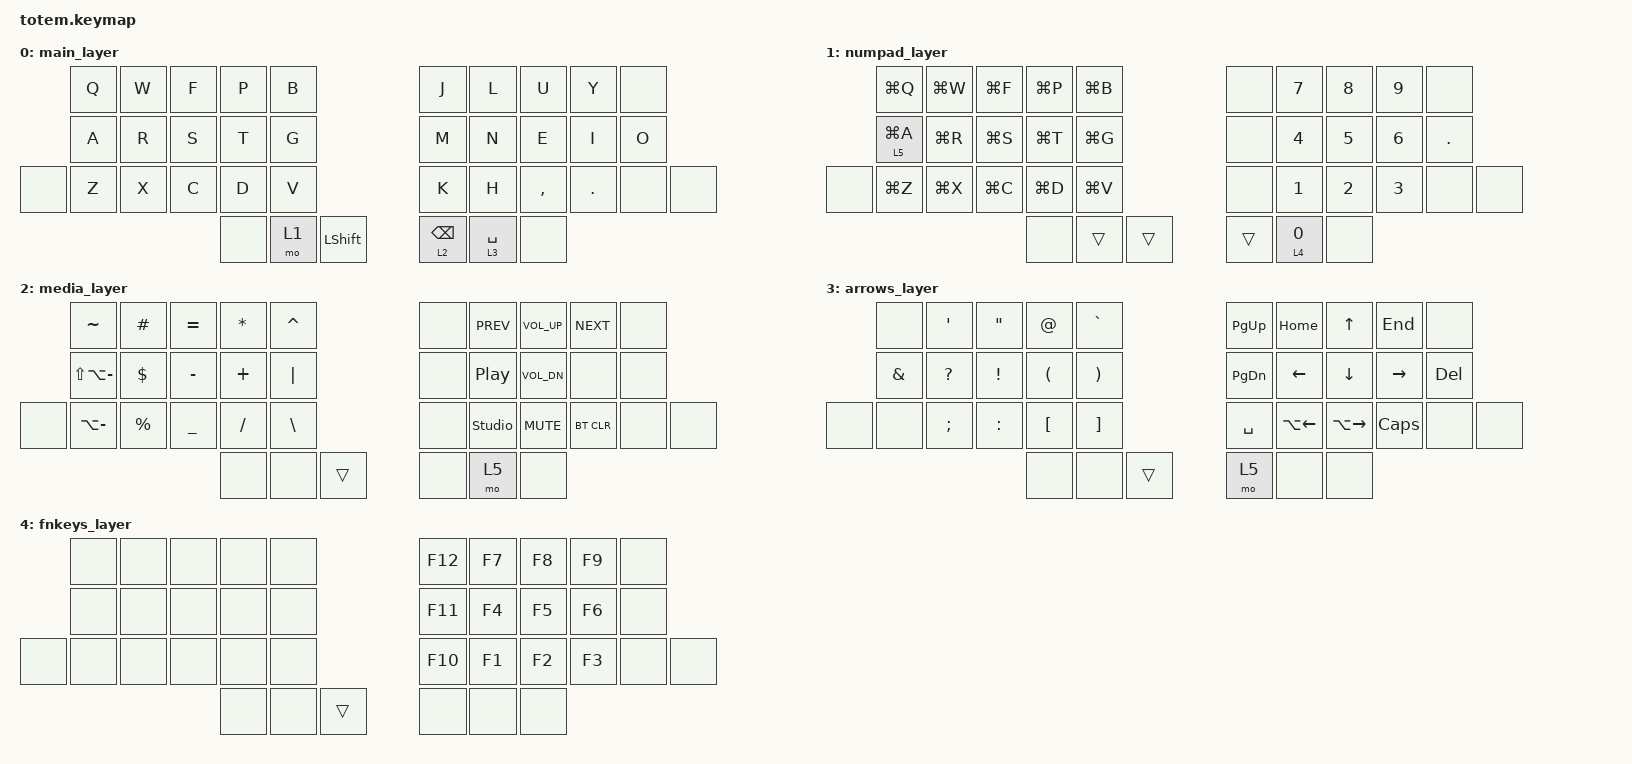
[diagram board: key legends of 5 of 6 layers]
//
//                                                        ▀▀▀▀▀     ▀▀▀▀▀          ▀▀█▀▀
//                                                        ▄▀▀▀▄  ▄  ▄▀▀▀▄  ▄  ▄▀▀▀▄  █  ▄▀▀▀▄
//                                                        █   █  █  █   █  █  █   █  █  █   █
//                                                         ▀▀▀   █   ▀▀▀   █   ▀▀▀   ▀   ▀▀▀
//                                                               █      ▄▄▄█▄▄▄    █   █  
//                                                               ▀      █  █  █     █▄█
//                                                             ▀▀▀▀▀    █  █  █      ▀
//                                                                      ▀  ▀  ▀
//
// ▄▄▄▄▄▄▄▄▄▄▄▄▄▄▄▄▄▄▄▄▄▄▄▄▄▄▄▄▄▄▄▄▄▄▄▄▄▄▄▄▄▄▄▄▄▄▄▄▄▄▄▄▄▄▄▄▄▄▄▄▄▄▄▄▄▄▄▄▄▄▄▄▄▄▄▄▄▄▄▄▄▄▄▄▄▄▄▄▄▄▄▄▄▄▄▄▄▄▄▄▄▄▄▄▄▄▄▄▄▄▄▄▄▄▄▄▄▄▄▄▄▄▄▄▄▄▄▄▄▄▄▄▄▄▄▄▄▄▄▄▄▄▄▄▄▄▄▄▄
       

#include <behaviors.dtsi> 
#include <dt-bindings/zmk/keys.h>
#include <dt-bindings/zmk/bt.h>
#include <dt-bindings/zmk/outputs.h>

#define MAIN 0
#define NUMPAD 1
#define MEDIA 2
#define ARROWS 3
#define FKEYS 4
#define LEFTARROWS 5

/*
     |  0 |  1 |  2 |  3 |  4 |    |  5 |  6 |  7 |  8 |  9 |
     | 10 | 11 | 12 | 13 | 14 |    | 15 | 16 | 17 | 18 | 19 |
| 20 | 21 | 22 | 23 | 24 | 25 |    | 26 | 27 | 28 | 29 | 30 | 31 | 
     |    |    | 32 | 33 | 34 |    | 35 | 36 | 37 |    |    | 
                                                                  */

/ {
    kscan0: kscan_0 {
        compatible = "zmk,kscan-gpio-matrix";
        label = "KSCAN";
        diode-direction = "col2row";
        wakeup-source;
    };
};


/ {
    combos {
        compatible = "zmk,combos";


        //Modifiers – Left Hand
        combo_lgui {
            timeout-ms = <25>;
            key-positions = <3 13>;
            layers = <0 1 2 3 4 5>;
            bindings = <&kp LGUI>;
        };
        combo_lalt {
            timeout-ms = <25>;
            key-positions = <2 12>;
            layers = <0 1 2 3 4 5>;
            bindings = <&kp LALT>;
        };
        combo_lctl {
            timeout-ms = <25>;
            key-positions = <1 11>;
            layers = <0 1 2 3 4 5>;
            bindings = <&kp LCTRL>;
        };
        combo_lctlalt {
            timeout-ms = <25>;
            key-positions = <1 11 2 12>;
            layers = <0 1 2 3 4 5>;
            bindings = <&kp LC(LALT)>;
        };
        combo_lctlgui {
            timeout-ms = <25>;
            key-positions = <1 11 3 13>;
            layers = <0 1 2 3 4 5>;
            bindings = <&kp LC(LGUI)>;
        };
        combo_laltgui {
            timeout-ms = <25>;
            key-positions = <2 12 3 13>;
            layers = <0 1 2 3 4 5>;
            bindings = <&kp LA(LGUI)>;
        };


        //Modifiers – Right Hand
        combo_rgui {
            timeout-ms = <25>;
            key-positions = <6 16>;
            layers = <0 1 2 3 4 5>;
            bindings = <&kp LGUI>;
        };
        combo_ralt {
            timeout-ms = <25>;
            key-positions = <7 17>;
            layers = <0 1 2 3 4 5>;
            bindings = <&kp RALT>;
        };
        combo_rctl {
            timeout-ms = <25>;
            key-positions = <8 18>;
            layers = <0 1 2 3 4 5>;
            bindings = <&kp RCTRL>;
        }; 
        combo_rctlralt {
            timeout-ms = <25>;
            key-positions = <8 18 7 17>;
            layers = <0 1 2 3 4 5>;
            bindings = <&kp RC(RALT)>;
        };
        combo_rctrgui {
            timeout-ms = <25>;
            key-positions = <8 18 6 16>;
            layers = <0 1 2 3 4 5>;
            bindings = <&kp RC(RGUI)>;
        };
        combo_raltrgui {
            timeout-ms = <25>;
            key-positions = <7 17 6 16>;
            layers = <0 1 2 3 4 5>;
            bindings = <&kp RA(RGUI)>;
        };


        //Control Keys – Right Hand
        combo_enter_right {
            timeout-ms = <25>;
            key-positions = <17 18>;
	    layers = <0 1 2 4>;
            bindings = <&kp ENTER>;
        };
        combo_tab_right {
            timeout-ms = <25>;
            key-positions = <17 29>;
	    layers = <0 1 2 4>;
            bindings = <&kp TAB>;
        };
        combo_shifttab_right {
            timeout-ms = <25>;
            key-positions = <16 17 29>;
	    layers = <0 1 2 4>;
            bindings = <&kp LS(TAB)>;
        };
        combo_escape_right {
            timeout-ms = <25>;
            key-positions = <7 8>;
	    layers = <0 1 2 4>;
            bindings = <&kp ESC>;
        };

// No pause/break, scrolllock, printscreen, numlock, insert     


        //Quotes
        combo_quote_curly_single_left {
            timeout-ms = <25>;
            key-positions = <7 16>;
	    layers = <0>;
            bindings = <&kp LA(RBKT)>;
        };
        combo_quote_curly_single_right {
            timeout-ms = <25>;
            key-positions = <7 18>;
	    layers = <0>;
            bindings = <&kp LS(LA(RBKT))>;
        };
        combo_quote_curly_double_left {
            timeout-ms = <25>;
            key-positions = <7 16>;
	    layers = <1>;
            bindings = <&kp LA(LBKT)>;
        };
        combo_quote_curly_double_right {
            timeout-ms = <25>;
            key-positions = <7 18>;
	    layers = <1>;
            bindings = <&kp LS(LA(LBKT))>;
        };
        combo_quote_regular_single {
            timeout-ms = <25>;
            key-positions = <7 15>;
	    layers = <0>;
            bindings = <&kp SQT>;
        };
        combo_quote_regular_double {
            timeout-ms = <25>;
            key-positions = <7 15>;
	    layers = <1>;
            bindings = <&kp LS(SQT)>;
        };


	//Symbols
        combo_semicolon {
            timeout-ms = <25>;
            key-positions = <28 29>;
	    layers = <0 1 2 4>;
            bindings = <&kp SEMI>;
        };
        combo_minus {
            timeout-ms = <25>;
            key-positions = <16 17>;
	    layers = <0 1 2 4>;
            bindings = <&kp MINUS>;
        };
        combo_equals {
            timeout-ms = <25>;
            key-positions = <6 7>;
	    layers = <0 1 2 4>;
            bindings = <&kp EQUAL>;
        };
        combo_plus {
            timeout-ms = <25>;
            key-positions = <16 18>;
	    layers = <0 1 2 4>;
            bindings = <&kp PLUS>;
        };
        combo_emdash {
            timeout-ms = <25>;
            key-positions = <16 17 19>;
 	    layers = <0>;
            bindings = <&kp LS(LA(MINUS))>;
        };
        combo_underscore {
            timeout-ms = <50>;
            key-positions = <27 28>;
	    layers = <0 1 2 4>;
            bindings = <&kp UNDER>;
        };
        combo_hash {
            timeout-ms = <25>;
            key-positions = <6 8>;
	    layers = <0 1 2 4>;
            bindings = <&kp HASH>;
        };
        combo_asterisk {
            timeout-ms = <25>;
            key-positions = <27 29>;
            layers = <0 1 2 4>;
            bindings = <&kp ASTERISK>;
        };
        combo_grave {
            timeout-ms = <25>;
            key-positions = <6 17>;
	    layers = <0 1 2 4>;
            bindings = <&kp GRAVE>;
        };
        combo_tilde {
            timeout-ms = <25>;
            key-positions = <16 17 8>;
            layers = <0 1 2 4>;
            bindings = <&kp TILDE>;
        };
        combo_slash {
            timeout-ms = <25>;
            key-positions = <17 18 27>;
            layers = <0 1 2 4>;
            bindings = <&kp SLASH>;
        };
        combo_backslash {
            timeout-ms = <25>;
            key-positions = <16 28 29>;
            layers = <0 1 2 4>;
            bindings = <&kp BACKSLASH>;
        };
        combo_pipe {
            timeout-ms = <25>;
            key-positions = <7 27>;
            layers = <0 1 2 4>;
            bindings = <&kp PIPE>;
        };
        combo_caret {
            timeout-ms = <25>;
            key-positions = <16 7 18>;
            layers = <0 1 2 4>;
            bindings = <&kp CARET>;
        }; 
        combo_percentsign {
            timeout-ms = <25>;
            key-positions = <27 18>;
            layers = <0 1 2 4>;
            bindings = <&kp PERCENT>;
        };
        combo_exclamationmark {
            timeout-ms = <25>;
            key-positions = <6 18>;
            layers = <0 1 2 4>;
            bindings = <&kp EXCLAMATION>;
        };
        combo_questionmark {
            timeout-ms = <25>;
            key-positions = <16 8>;
            layers = <0 1 2 4>;
            bindings = <&kp QUESTION>;
        };
        combo_dollarsign {
            timeout-ms = <25>;
            key-positions = <27 7 18>;
            layers = <0 1 2 4>;
            bindings = <&kp DOLLAR>;
        };
        combo_atsign {
            timeout-ms = <25>;
            key-positions = <6 17 18>;
            layers = <0 1 2 4>;
            bindings = <&kp AT_SIGN>;
        };
        combo_ampersand {
            timeout-ms = <25>;
            key-positions = <16 29>;
            layers = <0 1 2 4>;
            bindings = <&kp AMPERSAND>;
        };


        //Parentheses
        combo_lpar {
            timeout-ms = <25>;
            key-positions = <19 27>;
            layers = <0 1 2 4>;
            bindings = <&kp LPAR>;
        };
        combo_rpar {
            timeout-ms = <25>;
            key-positions = <19 28>;
            layers = <0 1 2 4>;
            bindings = <&kp RPAR>;
        };
        combo_lbkt {
            timeout-ms = <25>;
            key-positions = <19 6>;
            layers = <0 1 2 4>;
            bindings = <&kp LBKT>;
        };
        combo_rbkt {
            timeout-ms = <25>;
            key-positions = <19 7>;
            layers = <0 1 2 4>;
            bindings = <&kp RBKT>;
        };

        
        //Left Hand
        combo_enter_left {
            timeout-ms = <25>;
            key-positions = <11 12>;
            layers = <0>;
            bindings = <&kp ENTER>;
        };
        combo_tab_left {
            timeout-ms = <25>;
            key-positions = <12 22>;
            layers = <0 1 2 4>;
            bindings = <&kp LS(TAB)>;
        };
        combo_escape_left {
            timeout-ms = <25>;
            key-positions = <1 2 3>;
            layers = <0 1 2 4>;
            bindings = <&kp ESC>;
        };
        combo_space {
            timeout-ms = <25>;
            key-positions = <22 24>;
            layers = <0 1 2 4>;
            bindings = <&kp SPACE>;
        };
        combo_backspace_left {
            timeout-ms = <25>;
            key-positions = <22 23>;
            layers = <0 1 2 4>;
            bindings = <&kp BSPC>;
        };
        combo_equal_left {
            timeout-ms = <25>;
            key-positions = <2 3>;
            layers = <0 1 2 4>;
            bindings = <&kp EQUAL>;
        };
        combo_minus_left {
            timeout-ms = <25>;
            key-positions = <12 13>;
            layers = <0>;
            bindings = <&kp MINUS>;
        };        
        

        //Macros
        combo_gfemail {
            timeout-ms = <25>;
            key-positions = <6 13 18>;
            layers = <0>;
            bindings = <&gfemail>;
        };
        combo_handle {
            timeout-ms = <25>;
            key-positions = <13 6 17>;
            layers = <0>;
            bindings = <&gfhandle>;
        };
        combo_phonenum {
            timeout-ms = <25>;
            key-positions = <13 27 29>;
            layers = <0>;
            bindings = <&phonenum>;
        };
        combo_name {
            timeout-ms = <25>;
            key-positions = <13 27 17>;
            layers = <0>;
            bindings = <&gfname>;
        };
        combo_thumbsup {
            timeout-ms = <25>;
            key-positions = <8 27>;
            layers = <0>;
            bindings = <&thumbsup>;
        };


        //Misc
        combo_altbackspace2 {
            timeout-ms = <25>;
            key-positions = <27 28>;
	    layers = <3>;
            bindings = <&kp LA(BSPC)>;
        };
        combo_altdel {
            timeout-ms = <25>;
            key-positions = <28 29>;
	    layers = <3>;
            bindings = <&kp LA(DEL)>;
        };
        combo_bootloaderleft {
            timeout-ms = <25>;
            key-positions = <1 3 22 24>;
            layers = <0>;
            bindings = <&bootloader>;
        };
        combo_bootloaderright {
            timeout-ms = <25>;
            key-positions = <6 8 27 29>;
            layers = <0>;
            bindings = <&bootloader>;
        };


        //Misc – Left
        combo_screenshot_file {
            timeout-ms = <25>;
            key-positions = <2 24>;
            layers = <0>;
            bindings = <&kp LG(LS(N4))>;
        };
        combo_screenshot_clipboard {
            timeout-ms = <25>;
            key-positions = <11 2 24>;
            layers = <0>;
            bindings = <&kp LG(LS(LC(N4)))>;
        };
        combo_controlup {
            timeout-ms = <25>;
            key-positions = <11 2 13>;
            layers = <0>;
            bindings = <&kp LC(UP)>;
        };
        combo_guik {
            timeout-ms = <25>;
            key-positions = <11 24>;
            layers = <0>;
            bindings = <&kp LG(K)>;
        };
        combo_alt_backspace_left {
            timeout-ms = <25>;
            key-positions = <11 13>;
            layers = <0>;
            bindings = <&kp LA(BSPC)>;
        };
        combo_l {
            timeout-ms = <25>;
            key-positions = <3 14>;
            layers = <0>;
            bindings = <&kp L>;
        };

    };
};


/ {
    macros {
    
        gfemail: gfemail {
            label = "gfemail";
            compatible = "zmk,behavior-macro";
            #binding-cells = <0>;
            bindings
                = <&macro_tap_time 1>
                , <&macro_tap &kp G &kp F &kp O &kp L &kp G &kp E &kp R &kp T &kp AT_SIGN &kp G &kp M &kp A &kp I &kp L &kp DOT &kp C &kp O &kp M>
                ;
        };

        gfhandle: gfhandle {
            label = "gfhandle";
            compatible = "zmk,behavior-macro";
            #binding-cells = <0>;
            bindings
                = <&macro_tap_time 1>
                , <&macro_tap &kp G &kp F &kp O &kp L &kp G &kp E &kp R &kp T>
                ;
        };
    
        phonenum: phonenum {
            label = "phonenum";
            compatible = "zmk,behavior-macro";
            #binding-cells = <0>;
            bindings
                = <&macro_tap_time 1>
                , <&macro_tap &kp N6 &kp N0 &kp N8 &kp N3 &kp N0 &kp N1 &kp N5 &kp N4 &kp N2 &kp N8>
                ;
        };

        gfname: gfname {
            label = "gfname";
            compatible = "zmk,behavior-macro";
            #binding-cells = <0>;
            bindings
                = <&macro_tap_time 1>
                , <&macro_tap &kp LS(G) &kp A &kp V &kp I &kp N &kp SPACE &kp LS(F) &kp O &kp L &kp G &kp E &kp R &kp T>
                ;
        };

        thumbsup: thumbsup {
            label = "thumbsup";
            compatible = "zmk,behavior-macro";
            #binding-cells = <0>;
            bindings
                = <&macro_tap_time 1>
                , <&macro_tap &kp SEMI &kp Y &kp E &kp P>
                ;
        };

	
    };
};


/ {
    keymap {
        compatible = "zmk,keymap";
        label ="Default keymap";

        main_layer {
            bindings = <
                &kp Q  &kp W  &kp F  &kp P  &kp B                         &kp J  &kp L  &kp U      &kp Y    &none
                &kp A  &kp R  &kp S  &kp T  &kp G                         &kp M  &kp N  &kp E      &kp I    &kp O
         &none  &kp Z  &kp X  &kp C  &kp D  &kp V                         &kp K  &kp H  &kp COMMA  &kp DOT  &none  &none
                                     &none  &mo 1  &kp LSHFT  &lt 2 BSPC  &lt 3 SPACE  &none
            >;
        };
        
        numpad_layer {
            bindings = <
                &kp LG(Q)    &kp LG(W)  &kp LG(F)  &kp LG(P)  &kp LG(B)                  &none  &kp N7  &kp N8  &kp N9  &none 
                &lt 5 LG(A)  &kp LG(R)  &kp LG(S)  &kp LG(T)  &kp LG(G)                  &none  &kp N4  &kp N5  &kp N6  &kp DOT
         &none  &kp LG(Z)    &kp LG(X)  &kp LG(C)  &kp LG(D)  &kp LG(V)                  &none  &kp N1  &kp N2  &kp N3  &none    &none
                                                   &none      &trans     &trans  &trans  &lt 4 N0    &none
            >;
        };
        
        media_layer {
            bindings = <
                &kp TILDE          &kp HASH   &kp EQUAL  &kp ASTRK  &kp CARET                 &none  &kp C_PREV      &kp C_VOL_UP  &kp C_NEXT  &none
                &kp LS(LA(MINUS))  &kp DLLR   &kp MINUS  &kp PLUS   &kp PIPE                  &none  &kp C_PP        &kp C_VOL_DN  &none       &none
         &none  &kp LA(MINUS)      &kp PRCNT  &kp UNDER  &kp SLASH  &kp BSLH                  &none  &studio_unlock  &kp C_MUTE    &bt BT_CLR  &none   &none
                                  	                 &none      &none      &trans  &none  &mo 5  &none
            >;
        };

        arrows_layer {
            bindings = <
                &none     &kp SQT    &kp DQT    &kp AT_SIGN  &kp GRAVE                   &kp PG_UP  &kp HOME      &kp UP         &kp END    &none 
                &kp AMPS  &kp QMARK  &kp EXCL   &kp LPAR     &kp RPAR                    &kp PG_DN  &kp LEFT      &kp DOWN       &kp RIGHT  &kp DEL
         &none  &none     &kp SEMI   &kp COLON  &kp LBKT     &kp RBKT                    &kp SPACE  &kp LA(LEFT)  &kp LA(RIGHT)  &kp CAPS   &none   &none 
                                                &none        &none        &trans  &mo 5  &none      &none
            >;
        };
        
        fnkeys_layer {
            bindings = <
                &none  &none  &none  &none  &none                 &kp F12  &kp F7  &kp F8  &kp F9  &none
                &none  &none  &none  &none  &none                 &kp F11  &kp F4  &kp F5  &kp F6  &none
         &none  &none  &none  &none  &none  &none                 &kp F10  &kp F1  &kp F2  &kp F3  &none   &none
                                     &none  &none  &trans  &none  &none    &none
            >;
        };

	leftarrows_layer {
            bindings = <
                &none  &kp HOME  &kp UP    &kp END    &none                 &none  &none    &none    &none  &none
                &none  &kp LEFT  &kp DOWN  &kp RIGHT  &none                 &none  &none    &none    &none  &none
                &none  &none     &none     &none      &none                 &none  &none    &none    &none  &none
                                           &none      &none  &trans  &none  &none  &none
            >;
        };
               
    };
};
